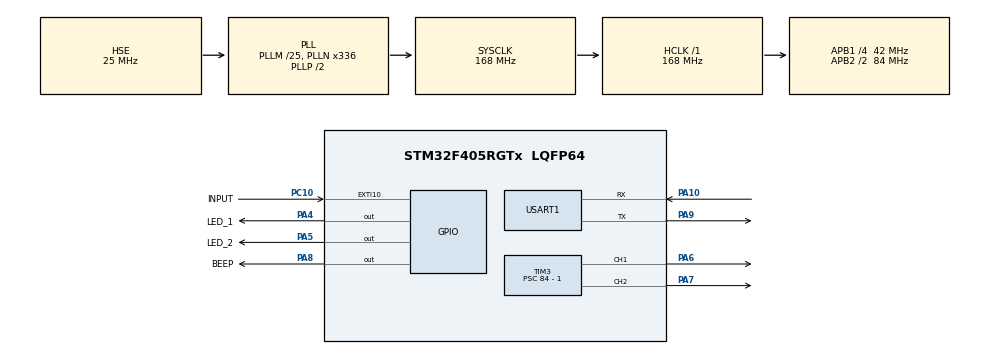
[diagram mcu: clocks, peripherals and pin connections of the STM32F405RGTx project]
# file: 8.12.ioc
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Dma.Request0=USART1_RX
Dma.Request1=USART1_TX
Dma.USART1_RX.0.Direction=DMA_PERIPH_TO_MEMORY
Dma.USART1_RX.0.FIFOMode=DMA_FIFOMODE_DISABLE
Dma.USART1_RX.0.Instance=DMA2_Stream2
Dma.USART1_RX.0.MemDataAlignment=DMA_MDATAALIGN_BYTE
Dma.USART1_RX.0.MemInc=DMA_MINC_ENABLE
Dma.USART1_RX.0.Mode=DMA_NORMAL
Dma.USART1_RX.0.PeriphDataAlignment=DMA_PDATAALIGN_BYTE
Dma.USART1_RX.0.PeriphInc=DMA_PINC_DISABLE
Dma.USART1_RX.0.Priority=DMA_PRIORITY_LOW
Dma.USART1_TX.1.Direction=DMA_MEMORY_TO_PERIPH
Dma.USART1_TX.1.FIFOMode=DMA_FIFOMODE_DISABLE
Dma.USART1_TX.1.Instance=DMA2_Stream7
Dma.USART1_TX.1.MemDataAlignment=DMA_MDATAALIGN_BYTE
Dma.USART1_TX.1.MemInc=DMA_MINC_ENABLE
Dma.USART1_TX.1.Mode=DMA_NORMAL
Dma.USART1_TX.1.PeriphDataAlignment=DMA_PDATAALIGN_BYTE
Dma.USART1_TX.1.PeriphInc=DMA_PINC_DISABLE
Dma.USART1_TX.1.Priority=DMA_PRIORITY_LOW
Mcu.Family=STM32F4
Mcu.Name=STM32F405RGTx
Mcu.Package=LQFP64
NVIC.DMA2_Stream2_IRQn=true\:0\:0\:false\:false\:true\:false\:true\:true
NVIC.DMA2_Stream7_IRQn=true\:0\:0\:false\:false\:true\:false\:true\:true
NVIC.PriorityGroup=NVIC_PRIORITYGROUP_4
NVIC.TIM1_UP_TIM10_IRQn=true\:15\:0\:false\:false\:true\:false\:true\:true
NVIC.TIM2_IRQn=true\:5\:0\:true\:false\:true\:true\:true\:true
NVIC.TimeBase=TIM1_UP_TIM10_IRQn
NVIC.TimeBaseIP=TIM1
NVIC.USART1_IRQn=true\:5\:0\:true\:false\:true\:true\:true\:true
PA10.GPIO_PuPd=GPIO_PULLUP
PA10.Mode=Asynchronous
PA10.Signal=USART1_RX
PA4.GPIO_Label=LED_1
PA4.GPIO_PuPd=GPIO_PULLDOWN
PA4.Signal=GPIO_Output
PA5.GPIO_Label=LED_2
PA5.GPIO_PuPd=GPIO_PULLDOWN
PA5.Signal=GPIO_Output
PA6.Signal=S_TIM3_CH1
PA7.Signal=S_TIM3_CH2
PA8.GPIO_Label=BEEP
PA8.GPIO_PuPd=GPIO_PULLDOWN
PA8.Signal=GPIO_Output
PA9.Mode=Asynchronous
PA9.Signal=USART1_TX
PC10.GPIO_Label=INPUT
PC10.GPIO_ModeDefaultEXTI=GPIO_MODE_IT_RISING_FALLING
PC10.GPIO_PuPd=GPIO_PULLUP
PC10.Signal=GPXTI10
PH0-OSC_IN.Mode=HSE-External-Oscillator
PH0-OSC_IN.Signal=RCC_OSC_IN
PH1-OSC_OUT.Mode=HSE-External-Oscillator
PH1-OSC_OUT.Signal=RCC_OSC_OUT
ProjectManager.HeapSize=0x800
ProjectManager.StackSize=0x400
ProjectManager.TargetToolchain=MDK-ARM V5.32
RCC.48MHZClocksFreq_Value=84000000
RCC.AHBFreq_Value=168000000
RCC.APB1CLKDivider=RCC_HCLK_DIV4
RCC.APB1Freq_Value=42000000
RCC.APB1TimFreq_Value=84000000
RCC.APB2CLKDivider=RCC_HCLK_DIV2
RCC.APB2Freq_Value=84000000
RCC.APB2TimFreq_Value=168000000
RCC.CortexFreq_Value=168000000
RCC.HCLKFreq_Value=168000000
RCC.HSE_VALUE=25000000
RCC.HSI_VALUE=16000000
RCC.LSE_VALUE=32768
RCC.PLLM=25
RCC.PLLN=336
RCC.PLLSourceVirtual=RCC_PLLSOURCE_HSE
RCC.SYSCLKFreq_VALUE=168000000
RCC.SYSCLKSource=RCC_SYSCLKSOURCE_PLLCLK
RCC.VCOOutputFreq_Value=336000000
SH.S_TIM3_CH1.0=TIM3_CH1,PWM Generation1 CH1
SH.S_TIM3_CH2.0=TIM3_CH2,PWM Generation2 CH2
TIM2.Period=2000-1
TIM2.Prescaler=84-1
TIM3.AutoReloadPreload=TIM_AUTORELOAD_PRELOAD_ENABLE
TIM3.Channel-PWM\ Generation1\ CH1=TIM_CHANNEL_1
TIM3.Channel-PWM\ Generation2\ CH2=TIM_CHANNEL_2
TIM3.OCFastMode_PWM-PWM\ Generation1\ CH1=TIM_OCFAST_DISABLE
TIM3.Period=1000 - 1
TIM3.Prescaler=84 - 1
USART1.VirtualMode=VM_ASYNC
VP_SYS_VS_tim1.Mode=TIM1
VP_TIM2_VS_ClockSourceINT.Mode=Internal
VP_TIM3_VS_ClockSourceINT.Mode=Internal
board=custom

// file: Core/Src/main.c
/* USER CODE BEGIN Header */
/**
  ******************************************************************************
  * @file           : main.c
  * @brief          : Main program body
  ******************************************************************************
  * @attention
  *
  * Copyright (c) 2026 STMicroelectronics.
  * All rights reserved.
  *
  * This software is licensed under terms that can be found in the LICENSE file
  * in the root directory of this software component.
  * If no LICENSE file comes with this software, it is provided AS-IS.
  *
  ******************************************************************************
  */
/* USER CODE END Header */
#include "main.h"
#include "dma.h"
#include "tim.h"
#include "usart.h"
#include "gpio.h"
#include "BEEP.h"

void SystemClock_Config(void);

int main(void)
{

  /* MCU Configuration--------------------------------------------------------*/

  /* Reset of all peripherals, Initializes the Flash interface and the Systick. */
  HAL_Init();

  /* USER CODE BEGIN Init */
  Beep_Init();
  /* USER CODE END Init */

  /* Configure the system clock */
  SystemClock_Config();

  /* Initialize all configured peripherals */
  MX_GPIO_Init();
  MX_DMA_Init();
  MX_TIM2_Init();
  MX_TIM3_Init();
  MX_USART1_UART_Init();
  /* USER CODE BEGIN 2 */
  float sin_value;
  uint8_t t_ms;
  /* USER CODE END 2 */

  /* Infinite loop */
  while (1)
  {

    /* USER CODE BEGIN 3 */
    sin_value = sinf(pi * t_ms * 0.01);
    UART_send_sin(sin_value);
    t_ms = (t_ms + 1) % 200U;
    HAL_Delay(1U);
  }
  /* USER CODE END 3 */
}

void SystemClock_Config(void)
{
  RCC_OscInitTypeDef RCC_OscInitStruct = {0};
  RCC_ClkInitTypeDef RCC_ClkInitStruct = {0};

  /** Configure the main internal regulator output voltage
  */
  __HAL_RCC_PWR_CLK_ENABLE();
  __HAL_PWR_VOLTAGESCALING_CONFIG(PWR_REGULATOR_VOLTAGE_SCALE1);

  /** Initializes the RCC Oscillators according to the specified parameters
  * in the RCC_OscInitTypeDef structure.
  */
  RCC_OscInitStruct.OscillatorType = RCC_OSCILLATORTYPE_HSE;
  RCC_OscInitStruct.HSEState = RCC_HSE_ON;
  RCC_OscInitStruct.PLL.PLLState = RCC_PLL_ON;
  RCC_OscInitStruct.PLL.PLLSource = RCC_PLLSOURCE_HSE;
  RCC_OscInitStruct.PLL.PLLM = 25;
  RCC_OscInitStruct.PLL.PLLN = 336;
  RCC_OscInitStruct.PLL.PLLP = RCC_PLLP_DIV2;
  RCC_OscInitStruct.PLL.PLLQ = 4;
  if (HAL_RCC_OscConfig(&RCC_OscInitStruct) != HAL_OK)
  {
    Error_Handler();
  }

  /** Initializes the CPU, AHB and APB buses clocks
  */
  RCC_ClkInitStruct.ClockType = RCC_CLOCKTYPE_HCLK|RCC_CLOCKTYPE_SYSCLK
                              |RCC_CLOCKTYPE_PCLK1|RCC_CLOCKTYPE_PCLK2;
  RCC_ClkInitStruct.SYSCLKSource = RCC_SYSCLKSOURCE_PLLCLK;
  RCC_ClkInitStruct.AHBCLKDivider = RCC_SYSCLK_DIV1;
  RCC_ClkInitStruct.APB1CLKDivider = RCC_HCLK_DIV4;
  RCC_ClkInitStruct.APB2CLKDivider = RCC_HCLK_DIV2;

  if (HAL_RCC_ClockConfig(&RCC_ClkInitStruct, FLASH_LATENCY_5) != HAL_OK)
  {
    Error_Handler();
  }
}

void HAL_TIM_PeriodElapsedCallback(TIM_HandleTypeDef *htim)
{
  if (htim->Instance == TIM1)
  {
    HAL_IncTick();
  }
}

void Error_Handler(void)
{
  __disable_irq();
  while (1)
  {
  }
}
